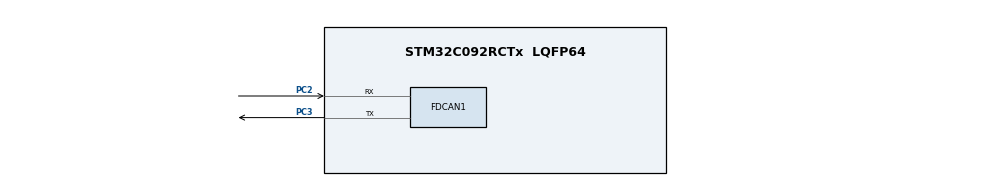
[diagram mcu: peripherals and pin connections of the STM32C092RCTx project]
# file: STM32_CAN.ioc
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FDCAN1.CalculateBaudRateNominal=500000
FDCAN1.CalculateTimeBitNominal=2000
FDCAN1.CalculateTimeQuantumNominal=666.6666666666666
FDCAN1.NominalPrescaler=8
Mcu.Family=STM32C0
Mcu.Name=STM32C092RCTx
Mcu.Package=LQFP64
NUCLEO-C092RC.BUTTON=1
NUCLEO-C092RC.LD1=true
NUCLEO-C092RC.LD2=true
NUCLEO-C092RC.VCP=true
NVIC.EXTI4_15_IRQn=true\:0\:0\:false\:false\:true\:false\:true\:true
PA13.GPIO_Label=SWDIO
PA13.Signal=DEBUG_SWDIO
PA14-BOOT0.GPIO_Label=SWCLK
PA14-BOOT0.Signal=DEBUG_SWCLK
PA2.Signal=USART2_TX
PA3.Signal=USART2_RX
PC14-OSCX_IN(PC14).GPIO_Label=OSCX_IN
PC14-OSCX_IN(PC14).Signal=RCC_OSCX_IN
PC15-OSCX_OUT(PC15).GPIO_Label=OSCX_OUT
PC15-OSCX_OUT(PC15).Signal=RCC_OSCX_OUT
PC2.Mode=FDCAN_Activate
PC2.Signal=FDCAN1_RX
PC3.Mode=FDCAN_Activate
PC3.Signal=FDCAN1_TX
PF0-OSC_IN(PF0).GPIO_Label=OSC_IN
PF0-OSC_IN(PF0).Signal=RCC_OSC_IN
PF1-OSC_OUT(PF1).GPIO_Label=OSC_OUT
PF1-OSC_OUT(PF1).Signal=RCC_OSC_OUT
ProjectManager.HeapSize=0x200
ProjectManager.StackSize=0x400
ProjectManager.TargetToolchain=STM32CubeIDE
RCC.ADCFreq_Value=12000000
RCC.AHBFreq_Value=12000000
RCC.CortexFreq_Value=12000000
RCC.EXTERNAL_CLOCK_VALUE=12288000
RCC.HCLKFreq_Value=12000000
RCC.HSE_VALUE=8000000
RCC.HSI_VALUE=48000000
RCC.LSE_VALUE=32768
RCC.SYSCLKFreq_VALUE=12000000
VP_NUCLEO-C092RC_VS_BSP_COMMON.Mode=COMMON
board=NUCLEO-C092RC

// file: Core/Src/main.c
/* USER CODE BEGIN Header */
/**
  ******************************************************************************
  * @file           : main.c
  * @brief          : Main program body
  ******************************************************************************
  * @attention
  *
  * Copyright (c) 2026 STMicroelectronics.
  * All rights reserved.
  *
  * This software is licensed under terms that can be found in the LICENSE file
  * in the root directory of this software component.
  * If no LICENSE file comes with this software, it is provided AS-IS.
  *
  ******************************************************************************
  */
/* USER CODE END Header */

#include "main.h"

/* USER CODE BEGIN Includes */
#include <stdio.h>
/* USER CODE END Includes */

/* USER CODE BEGIN PD */

/* *** Change this to 1 or 2 before flashing each board *** */
#define BOARD_ID  2

#if BOARD_ID == 1
  #define MY_CAN_ID      0x100U   /* this board transmits with this ID      */
  #define PARTNER_CAN_ID 0x101U   /* expect messages from the partner board */
#elif BOARD_ID == 2
  #define MY_CAN_ID      0x101U
  #define PARTNER_CAN_ID 0x100U
#else
  #error "BOARD_ID must be 1 or 2"
#endif

/* USER CODE END PD */

COM_InitTypeDef BspCOMInit;

FDCAN_HandleTypeDef hfdcan1;

/* USER CODE BEGIN PV */

FDCAN_TxHeaderTypeDef TxHeader;
FDCAN_RxHeaderTypeDef RxHeader;

/* Payload: magic header + board ID + 16-bit counter + 2 spare bytes */
uint8_t TxData[8] = {0xDE, 0xAD, 0xBE, 0xEF, BOARD_ID, 0x00, 0x00, 0x00};
uint8_t RxData[8];

/* USER CODE END PV */

void SystemClock_Config(void);
static void MX_GPIO_Init(void);
static void MX_FDCAN1_Init(void);

int main(void)
{

  /* MCU Configuration--------------------------------------------------------*/

  /* Reset of all peripherals, Initializes the Flash interface and the Systick. */
  HAL_Init();

  /* Configure the system clock */
  SystemClock_Config();

  /* Initialize all configured peripherals */
  MX_GPIO_Init();
  MX_FDCAN1_Init();

  /* USER CODE BEGIN 2 */

  /* Configure acceptance filter: accept ALL standard frames into RX FIFO 0.
     FilterID2 = 0x000 is the mask — every bit is "don't care", so every
     standard frame passes regardless of its identifier.                    */
  FDCAN_FilterTypeDef sFilterConfig;
  sFilterConfig.IdType       = FDCAN_STANDARD_ID;
  sFilterConfig.FilterIndex  = 0;
  sFilterConfig.FilterType   = FDCAN_FILTER_MASK;
  sFilterConfig.FilterConfig = FDCAN_FILTER_TO_RXFIFO0;
  sFilterConfig.FilterID1    = 0x000U;   /* filter value  (don't care) */
  sFilterConfig.FilterID2    = 0x000U;   /* mask = 0 → accept all IDs */
  if (HAL_FDCAN_ConfigFilter(&hfdcan1, &sFilterConfig) != HAL_OK)
  {
    Error_Handler();
  }

  /* Route any non-matching standard frame to FIFO 0 as well (belt + suspenders) */
  if (HAL_FDCAN_ConfigGlobalFilter(&hfdcan1,
                                    FDCAN_ACCEPT_IN_RX_FIFO0,
                                    FDCAN_REJECT,
                                    FDCAN_FILTER_REMOTE,
                                    FDCAN_FILTER_REMOTE) != HAL_OK)
  {
    Error_Handler();
  }

  /* Start the FDCAN peripheral */
  if (HAL_FDCAN_Start(&hfdcan1) != HAL_OK)
  {
    Error_Handler();
  }

  /* Pre-fill TX header — only the payload changes per send */
  TxHeader.Identifier          = MY_CAN_ID;
  TxHeader.IdType              = FDCAN_STANDARD_ID;
  TxHeader.TxFrameType         = FDCAN_DATA_FRAME;
  TxHeader.DataLength          = FDCAN_DLC_BYTES_8;
  TxHeader.ErrorStateIndicator = FDCAN_ESI_ACTIVE;
  TxHeader.BitRateSwitch       = FDCAN_BRS_OFF;
  TxHeader.FDFormat             = FDCAN_CLASSIC_CAN;
  TxHeader.TxEventFifoControl  = FDCAN_NO_TX_EVENTS;
  TxHeader.MessageMarker       = 0;

  /* USER CODE END 2 */

  /* Initialize leds */
  BSP_LED_Init(LED_GREEN);
  BSP_LED_Init(LED_BLUE);

  /* Initialize USER push-button in GPIO polling mode */
  BSP_PB_Init(BUTTON_USER, BUTTON_MODE_GPIO);

  /* Initialize COM1 port (115200, 8N1) */
  BspCOMInit.BaudRate   = 115200;
  BspCOMInit.WordLength = COM_WORDLENGTH_8B;
  BspCOMInit.StopBits   = COM_STOPBITS_1;
  BspCOMInit.Parity     = COM_PARITY_NONE;
  BspCOMInit.HwFlowCtl  = COM_HWCONTROL_NONE;
  if (BSP_COM_Init(COM1, &BspCOMInit) != BSP_ERROR_NONE)
  {
    Error_Handler();
  }

  /* USER CODE BEGIN WHILE_INIT */
  printf("\r\n=== HW12 CAN Demo  (Board %d) ===\r\n", BOARD_ID);
  printf("MY_CAN_ID      = 0x%03X\r\n", MY_CAN_ID);
  printf("PARTNER_CAN_ID = 0x%03X\r\n", PARTNER_CAN_ID);
  printf("Press USER button to transmit.\r\n\r\n");

  uint32_t tx_count = 0;
  uint8_t  btn_prev = 0;
  /* USER CODE END WHILE_INIT */

  /* Infinite loop */
  /* USER CODE BEGIN WHILE */
  while (1)
  {
    /* ------------------------------------------------------------------ */
    /* TX: send a CAN frame when the USER button is pressed (rising edge)  */
    /* ------------------------------------------------------------------ */
    uint8_t btn_curr = BSP_PB_GetState(BUTTON_USER);

    if (btn_curr == 1 && btn_prev == 0)
    {
      /* Embed a running counter in bytes [5:6] so the partner can verify
         message ordering.                                                 */
      TxData[5] = (uint8_t)((tx_count >> 8) & 0xFF);
      TxData[6] = (uint8_t)( tx_count       & 0xFF);
      tx_count++;

      if (HAL_FDCAN_AddMessageToTxFifoQ(&hfdcan1, &TxHeader, TxData) == HAL_OK)
      {
        BSP_LED_On(LED_GREEN);
        printf("[TX #%lu] ID=0x%03X  %02X %02X %02X %02X %02X %02X %02X %02X\r\n",
               (unsigned long)(tx_count - 1U),
               MY_CAN_ID,
               TxData[0], TxData[1], TxData[2], TxData[3],
               TxData[4], TxData[5], TxData[6], TxData[7]);
        HAL_Delay(100);
        BSP_LED_Off(LED_GREEN);
      }
      else
      {
        printf("[TX ERROR] Could not enqueue — TX FIFO full?\r\n");
      }
    }
    btn_prev = btn_curr;

    /* ------------------------------------------------------------------ */
    /* RX: drain RX FIFO 0 and print any incoming frames                   */
    /* ------------------------------------------------------------------ */
    while (HAL_FDCAN_GetRxFifoFillLevel(&hfdcan1, FDCAN_RX_FIFO0) > 0)
    {
      if (HAL_FDCAN_GetRxMessage(&hfdcan1, FDCAN_RX_FIFO0, &RxHeader, RxData) == HAL_OK)
      {
        BSP_LED_On(LED_BLUE);
        printf("[RX]      ID=0x%03X  %02X %02X %02X %02X %02X %02X %02X %02X\r\n",
               (unsigned int)RxHeader.Identifier,
               RxData[0], RxData[1], RxData[2], RxData[3],
               RxData[4], RxData[5], RxData[6], RxData[7]);
        HAL_Delay(100);
        BSP_LED_Off(LED_BLUE);
      }
    }

    HAL_Delay(10); /* button debounce + yield */

    /* USER CODE END WHILE */

  }
}

void SystemClock_Config(void)
{
  RCC_OscInitTypeDef RCC_OscInitStruct = {0};
  RCC_ClkInitTypeDef RCC_ClkInitStruct = {0};

  __HAL_FLASH_SET_LATENCY(FLASH_LATENCY_0);

  /** Initializes the RCC Oscillators according to the specified parameters
  * in the RCC_OscInitTypeDef structure.
  */
  RCC_OscInitStruct.OscillatorType = RCC_OSCILLATORTYPE_HSI;
  RCC_OscInitStruct.HSIState = RCC_HSI_ON;
  RCC_OscInitStruct.HSIDiv = RCC_HSI_DIV4;
  RCC_OscInitStruct.HSICalibrationValue = RCC_HSICALIBRATION_DEFAULT;
  if (HAL_RCC_OscConfig(&RCC_OscInitStruct) != HAL_OK)
  {
    Error_Handler();
  }

  /** Initializes the CPU, AHB and APB buses clocks
  */
  RCC_ClkInitStruct.ClockType = RCC_CLOCKTYPE_HCLK|RCC_CLOCKTYPE_SYSCLK
                              |RCC_CLOCKTYPE_PCLK1;
  RCC_ClkInitStruct.SYSCLKSource = RCC_SYSCLKSOURCE_HSI;
  RCC_ClkInitStruct.SYSCLKDivider = RCC_SYSCLK_DIV1;
  RCC_ClkInitStruct.AHBCLKDivider = RCC_HCLK_DIV1;
  RCC_ClkInitStruct.APB1CLKDivider = RCC_APB1_DIV1;

  if (HAL_RCC_ClockConfig(&RCC_ClkInitStruct, FLASH_LATENCY_0) != HAL_OK)
  {
    Error_Handler();
  }
}

static void MX_FDCAN1_Init(void)
{

  hfdcan1.Instance = FDCAN1;
  hfdcan1.Init.ClockDivider = FDCAN_CLOCK_DIV1;
  hfdcan1.Init.FrameFormat = FDCAN_FRAME_CLASSIC;
  hfdcan1.Init.Mode = FDCAN_MODE_NORMAL;
  hfdcan1.Init.AutoRetransmission = ENABLE;   /* retry on arbitration loss */
  hfdcan1.Init.TransmitPause = DISABLE;
  hfdcan1.Init.ProtocolException = DISABLE;
  /* Baud = FDCAN_CLK / (Prescaler * (1 + TimeSeg1 + TimeSeg2))
           = 12 MHz  / (8        * (1 + 1        + 1        ))
           = 500 kbps                                           */
  hfdcan1.Init.NominalPrescaler = 8;
  hfdcan1.Init.NominalSyncJumpWidth = 1;
  hfdcan1.Init.NominalTimeSeg1 = 1;
  hfdcan1.Init.NominalTimeSeg2 = 1;
  hfdcan1.Init.DataPrescaler = 1;
  hfdcan1.Init.DataSyncJumpWidth = 1;
  hfdcan1.Init.DataTimeSeg1 = 1;
  hfdcan1.Init.DataTimeSeg2 = 1;
  hfdcan1.Init.StdFiltersNbr = 1;   /* one standard-ID filter (accept all) */
  hfdcan1.Init.ExtFiltersNbr = 0;
  hfdcan1.Init.TxFifoQueueMode = FDCAN_TX_FIFO_OPERATION;
  if (HAL_FDCAN_Init(&hfdcan1) != HAL_OK)
  {
    Error_Handler();
  }

}

static void MX_GPIO_Init(void)
{

  /* GPIO Ports Clock Enable */
  __HAL_RCC_GPIOC_CLK_ENABLE();
  __HAL_RCC_GPIOF_CLK_ENABLE();
  __HAL_RCC_GPIOA_CLK_ENABLE();

}

/* USER CODE BEGIN 4 */

/* __io_putchar is already defined in Drivers/BSP/STM32C0xx_Nucleo/stm32c0xx_nucleo.c
   and routes to COM1 UART — no redefinition needed here.                             */

/* USER CODE END 4 */

void Error_Handler(void)
{
  __disable_irq();
  while (1)
  {
  }
}
